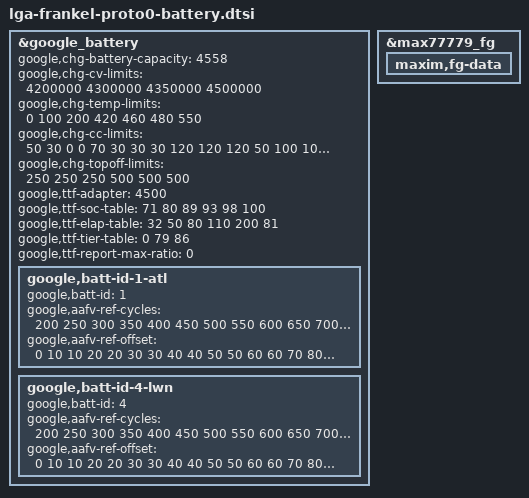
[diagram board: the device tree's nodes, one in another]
// SPDX-License-Identifier: GPL-2.0-only
/*
 * Battery device tree entries specific to Frankel Proto0
 *
 * Copyright 2024 Google LLC
 *
 */

&google_battery {
	google,chg-battery-capacity = <4558>;

	google,chg-cv-limits = <4200000 4300000 4350000 4500000>;
	google,chg-temp-limits = <0 100 200 420 460 480 550>;
	google,chg-cc-limits = <
		 50   30    0    0
		 70   30   30   30
		120  120  120   50
		100  100  100   50
		 50   50    0    0
		 30    0    0    0
	>;

	google,chg-topoff-limits = <250 250 250 500 500 500>;
	google,ttf-adapter = <4500>;
	google,ttf-soc-table =  <71 80 89 93  98  100>;
	google,ttf-elap-table = <32 50 80 110 200 81>;
	google,ttf-tier-table = <0 79 86>;
	google,ttf-report-max-ratio = <0>;

	google,batt-id-1-atl {
		google,batt-id = <1>;
		google,aafv-ref-cycles = <
			200  250  300  350  400  450  500  550
			600  650  700  750  800  850  900  950
		>;
		google,aafv-ref-offset = <
			  0  10  10  20  20  30  30  40
			 40  50  50  60  60  70  80  90
		>;
	};
	google,batt-id-4-lwn {
		google,batt-id = <4>;
		google,aafv-ref-cycles = <
			200  250  300  350  400  450  500  550
			600  650  700  750  800  850  900  950
		>;
		google,aafv-ref-offset = <
			  0  10  10  20  20  30  30  40
			 40  50  50  60  60  70  80  90
		>;
	};
};

&max77779_fg {
	maxim,fg-data {
		#include "google-base/platform/lga-tokay-battery-data.dtsi"
	};
};
